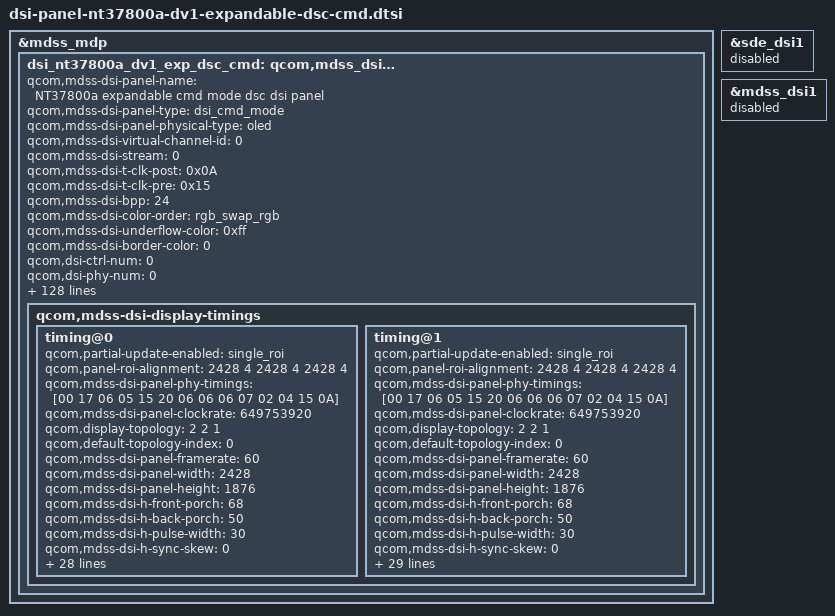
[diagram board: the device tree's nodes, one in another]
/* Copyright (c) 2014, Code Aurora Forum. All rights reserved.
 *
 * This program is free software; you can redistribute it and/or modify
 * it under the terms of the GNU General Public License version 2 and
 * only version 2 as published by the Free Software Foundation.
 *
 * This program is distributed in the hope that it will be useful,
 * but WITHOUT ANY WARRANTY; without even the implied warranty of
 * MERCHANTABILITY or FITNESS FOR A PARTICULAR PURPOSE.  See the
 * GNU General Public License for more details.
 */

/*
 * ===== 2nd working sample information =====
 *   [ DAh : 0x02, DBh : 0x01, DCh : 0x01 ]
 *  A. IRC(VDC) : not supported
 *  B. CM : supported
 *  C. Demura : White Demura
 *  D. PPA : supported
 *  E. AoD Band : not supported
 */
&mdss_mdp {
    dsi_nt37800a_dv1_exp_dsc_cmd: qcom,mdss_dsi_nt37800a_dv1_exp_dsc_cmd {
    qcom,mdss-dsi-panel-name = "NT37800a expandable cmd mode dsc dsi panel";
		qcom,mdss-dsi-panel-type = "dsi_cmd_mode";
		qcom,mdss-dsi-panel-physical-type = "oled";
		qcom,mdss-dsi-virtual-channel-id = <0>;
		qcom,mdss-dsi-stream = <0>;
		qcom,mdss-dsi-t-clk-post = <0x0A>;
		qcom,mdss-dsi-t-clk-pre = <0x15>;
		qcom,mdss-dsi-bpp = <24>;
		qcom,mdss-dsi-color-order = "rgb_swap_rgb";
		qcom,mdss-dsi-underflow-color = <0xff>;
		qcom,mdss-dsi-border-color = <0>;
		qcom,dsi-ctrl-num = <0>;
		qcom,dsi-phy-num = <0>;
		qcom,dsi-select-clocks = "mux_byte_clk0", "mux_pixel_clk0";
		qcom,mdss-dsi-traffic-mode = "burst_mode";
		qcom,mdss-dsi-lane-map = "lane_map_0123";
		qcom,mdss-dsi-bllp-eof-power-mode;
		qcom,mdss-dsi-bllp-power-mode;
		qcom,mdss-dsi-lane-0-state;
		qcom,mdss-dsi-lane-1-state;
		qcom,mdss-dsi-lane-2-state;
		qcom,mdss-dsi-lane-3-state;
		qcom,mdss-dsi-reset-sequence = <1 10>, <0 2>, <1 10>;
		qcom,mdss-dsi-dma-trigger = "trigger_sw";
		qcom,mdss-dsi-mdp-trigger = "none";
		qcom,mdss-dsi-te-pin-select = <1>;
		qcom,mdss-dsi-wr-mem-start = <0x2c>;
		qcom,mdss-dsi-wr-mem-continue = <0x3c>;
		qcom,mdss-dsi-te-dcs-command = <1>;
		//qcom,mdss-dsi-te-check-enable;
		//qcom,mdss-dsi-te-using-te-pin;
		qcom,mdss-dsi-lp11-init;
		qcom,mdss-dsi-tx-eot-append;
		qcom,ulps-enabled;

		/***************************** HDR *******************************/
		qcom,mdss-dsi-panel-hdr-enabled;
		qcom,mdss-dsi-panel-hdr-color-primaries = <14500 15500 32000
			17000 15500 30000 8000 3000>;
		qcom,mdss-dsi-panel-peak-brightness = <4200000>;
		qcom,mdss-dsi-panel-blackness-level = <3230>;

		qcom,mdss-pan-physical-width-dimension = <156>;
		qcom,mdss-pan-physical-height-dimension = <121>;

		/***************** Display Control ***********************/
		lge,mdss-dsi-reset-keep-high-after-off-cmd = <180>;

		lge,mdss-dsi-disp-ctrl-command-1 = [
			15 01 00 00 00 00 02 53 20
		];
		lge,mdss-dsi-disp-ctrl-command-1-state = "dsi_lp_mode";
		lge,mdss-dsi-disp-ctrl-command-2 = [
			15 01 00 00 00 00 02 55 00
			39 00 00 00 00 00 06 F0 55 AA 52 08 00
			15 00 00 00 00 00 02 6F 03
			39 00 00 00 00 00 02 D3 00
			39 01 00 00 00 00 06 F0 55 AA 52 00 00
		];
		lge,mdss-dsi-disp-ctrl-command-2-state = "dsi_lp_mode";

		/***************** Color Manager ***********************/
		lge,use-expandscreen-control;
		lge,use-color-manager;
		lge,color-manager-default-status = <1>;
		lge,mdss-dsi-color-manager-mode-table = <0 1>, <1 1>, <2 1>, <3 1>;

		lge,mdss-dsi-saturation-command = [
		39 00 00 00 00 00 06 F0 55 AA 52 08 00
		39 00 00 00 00 00 2E D1 38 36 37 37 36 36 36 39 33 29 2D 29 26 31 33 35 35 36 36 36 36 34 35 35 01 01 01 01 01 01 01 01 01 01 01 01 01 06 0C 03 09 0F 68 88 00
		39 01 00 00 00 00 06 F0 55 AA 52 00 00
		];
		lge,mdss-dsi-saturation-command-state = "dsi_hs_mode";

		lge,mdss-dsi-hue-command = [
		39 00 00 00 00 00 06 F0 55 AA 52 08 00
		39 00 00 00 00 00 34 D2 77 0C 40 96 83 93 80 7E 63 58 40 40 40 68 7E 78 94 94 94 8C 7A 7A 7A 7A 7D 86 8A 80 80 80 80 80 80 80 80 80 80 80 80 80 80 80 80 80 80 80 80 80 80 80 80
		39 01 00 00 00 00 06 F0 55 AA 52 00 00
		];
		lge,mdss-dsi-hue-command-state = "dsi_hs_mode";

		lge,mdss-dsi-sharpness-command = [
		39 00 00 00 00 00 06 F0 55 AA 52 08 00
		39 00 00 00 00 00 07 D3 02 00 00 01 10 00
		39 01 00 00 00 00 06 F0 55 AA 52 00 00
		];
		lge,mdss-dsi-sharpness-command-state = "dsi_hs_mode";

		lge,mdss-dsi-cm-natural = [
		39 00 00 00 00 00 06 F0 55 AA 52 08 00
		15 00 00 00 00 00 02 6F 00
		39 00 00 00 00 00 13 CE 00 40 40 40 40 3D 3D 3D 3D 40 40 40 40 40 40 40 40 40
		15 00 00 00 00 00 02 6F 13
		39 00 00 00 00 00 12 CE 45 45 45 45 45 45 45 45 45 45 45 45 45 45 45 45 40
		15 00 00 00 00 00 02 6F 24
		39 00 00 00 00 00 12 CE 42 42 42 42 42 42 42 42 42 42 42 42 42 42 42 40 40
		15 00 00 00 00 00 02 6F 35
		39 00 00 00 00 00 12 CE 40 40 40 40 40 40 40 40 40 40 40 40 40 40 40 40 40
		39 00 00 00 00 00 2E D1 38 36 37 37 36 36 36 39 33 29 2D 29 26 31 33 35 35 36 36 36 36 34 35 35 01 01 01 01 01 01 01 01 01 01 01 01 01 06 0C 03 09 0F 68 88 00
		39 00 00 00 00 00 34 D2 77 0C 40 96 83 93 80 7E 63 58 40 40 40 68 7E 78 94 94 94 8C 7A 7A 7A 7A 7D 86 8A 80 80 80 80 80 80 80 80 80 80 80 80 80 80 80 80 80 80 80 80 80 80 80 80
		39 01 00 00 00 00 06 F0 55 AA 52 00 00
		];
		lge,mdss-dsi-cm-natural-state = "dsi_hs_mode";

		lge,mdss-dsi-cm-vivid = [
		39 00 00 00 00 00 06 F0 55 AA 52 08 00
		15 00 00 00 00 00 02 6F 00
		39 00 00 00 00 00 13 CE 00 40 40 40 40 40 40 40 40 40 40 40 40 40 40 40 40 40
		15 00 00 00 00 00 02 6F 13
		39 00 00 00 00 00 12 CE 40 40 40 40 40 40 40 40 40 40 40 40 40 40 40 40 40
		15 00 00 00 00 00 02 6F 24
		39 00 00 00 00 00 12 CE 40 40 40 40 40 40 40 40 40 40 40 40 40 40 40 40 40
		15 00 00 00 00 00 02 6F 35
		39 00 00 00 00 00 12 CE 40 40 40 40 40 40 40 40 40 40 40 40 40 40 40 40 40
		39 00 00 00 00 00 2E D1 50 35 35 35 50 50 50 50 50 50 50 50 50 50 50 50 50 50 50 50 50 50 50 50 01 01 01 01 01 01 01 01 01 01 01 01 00 06 0C 03 09 0F 68 88 00
		39 00 00 00 00 00 34 D2 77 0C 40 80 80 95 80 80 80 80 80 80 80 80 80 80 80 80 80 80 80 80 80 80 80 80 80 80 80 80 80 80 80 80 80 80 80 80 80 80 80 80 80 80 80 80 80 80 80 80 80
		39 01 00 00 00 00 06 F0 55 AA 52 00 00
		];
		lge,mdss-dsi-cm-vivid-state = "dsi_hs_mode";

		lge,mdss-dsi-cm-cinema = [
		39 00 00 00 00 00 06 F0 55 AA 52 08 00
		15 00 00 00 00 00 02 6F 00
		39 00 00 00 00 00 13 CE 00 40 40 44 44 44 44 44 44 44 44 44 44 44 44 44 44 40
		15 00 00 00 00 00 02 6F 13
		39 00 00 00 00 00 12 CE 40 40 40 40 40 40 40 40 40 40 40 40 40 40 40 40 40
		15 00 00 00 00 00 02 6F 24
		39 00 00 00 00 00 12 CE 43 43 43 43 43 43 43 43 43 43 43 48 48 48 48 48 50
		15 00 00 00 00 00 02 6F 35
		39 00 00 00 00 00 12 CE 44 44 44 44 44 44 44 44 44 44 44 44 44 44 44 44 45
		39 00 00 00 00 00 2E D1 35 35 35 35 35 35 37 37 38 35 30 2C 2C 2C 30 32 35 35 35 35 35 34 33 35 44 14 11 11 11 11 11 15 11 11 21 44 00 06 0C 03 09 0F 68 88 00
		39 00 00 00 00 00 34 D2 77 0C 40 80 80 8D 85 80 80 70 60 50 60 7A 80 80 80 8A 8A 8A 80 7B 7B 78 76 74 80 80 80 80 80 80 80 80 80 80 80 80 80 80 80 80 80 80 80 80 80 80 80 80 80
		39 01 00 00 00 00 06 F0 55 AA 52 00 00
		];
		lge,mdss-dsi-cm-cinema-state = "dsi_hs_mode";

		/************************ Brightness ******************************/
		/* Brightness Map List */
		lge,blmap = <
			0
			16 16 16 16 16 16 16 16 16 16 16 16 16 16 16 17 17 18 18 19
			19 21 22 24 26 29 31 34 36 39 42 44 47 50 53 56 60 63 66 69
			72 75 79 82 85 88 91 94 98 102 106 110 114 119 123 127 132 136 141 145
			149 153 158 162 167 171 176 180 185 189 194 198 203 207 211 216 221 225 229 234
			239 243 248 252 257 261 266 270 275 279 284 288 292 297 301 306 310 314 319 324
			329 334 339 344 349 353 358 363 367 372 377 381 386 390 395 400 404 408 413 417
			422 427 432 438 443 448 453 458 463 468 473 478 483 488 493 498 503 508 513 518
			522 527 532 537 542 546 551 555 560 565 570 575 580 584 589 594 599 604 608 613
			618 623 628 632 637 642 647 651 656 661 665 670 674 679 683 688 692 697 701 706
			710 715 719 723 728 732 737 741 745 749 753 757 762 766 770 775 779 783 787 792
			796 800 804 808 812 816 820 824 829 833 837 841 846 850 855 859 863 868 872 876
			880 884 889 893 897 902 906 910 914 918 923 927 931 936 940 944 948 952 956 960
			965 969 973 977 982 986 990 994 998 1002 1006 1011 1015 1019 1024 1024 1024 1024 1024 1024
			1024 1024 1024 1024 1024 1024 1024 1024 1025 1025 1025 1025 1025 1025 1026 1026 1026 1026 1027 1027
			1027 1028 1028 1028 1029 1029 1030 1030 1030 1031 1031 1032 1032 1033 1033 1034 1035 1035 1036 1036
			1037 1038 1038 1039 1040 1041 1042 1043 1043 1044 1045 1046 1047 1048 1050 1051 1052 1053 1054 1055
			1056 1058 1059 1094 1126 1151 1184 1227 1261 1283 1320 1351 1406 1428 1474 1508 1531 1571 1612 1656
			1678 1742 1751 1803 1846 1888 1915 1978 2027 2049 2121 2145 2194 2239 2285 2342 2381 2433 2486 2528
			2558 2623 2651 2729 2756
		>;

		lge,blmap-hl = <
			0
			50 50 50 50 50 50 50 50 50 50 50 50 51 52 52 54 55 57 59 60
			62 65 67 70 73 76 79 82 85 89 92 96 100 105 110 115 121 126 131 137
			142 148 153 159 165 171 177 183 188 194 200 206 212 219 225 231 237 243 249 255
			262 268 274 280 286 292 299 305 311 317 324 331 338 345 351 358 364 371 377 384
			390 397 403 409 415 422 429 437 444 451 459 466 473 480 487 494 501 508 515 522
			528 535 542 548 555 562 569 576 582 589 596 603 610 617 624 630 637 644 651 657
			664 670 677 683 690 696 702 709 715 721 728 734 740 746 752 758 764 770 776 782
			788 794 800 806 812 818 824 830 835 842 848 855 861 867 873 879 885 891 897 903
			909 915 921 927 934 940 946 952 958 964 970 976 982 988 993 999 1005 1012 1018 1024
			1030 1036 1042 1049 1057 1187 1369 1553 1742 1896 2093 2264 2448 2627 2791 2973 3165 3338 3547 3715
			3923 4078 4078 4078 4078 4078 4078 4078 4078 4078 4078 4078 4078 4078 4078 4078 4078 4078 4078 4078
			4078 4078 4078 4078 4078 4078 4078 4078 4078 4078 4078 4078 4078 4078 4078 4078 4078 4078 4078 4078
			4078 4078 4078 4078 4078 4078 4078 4078 4078 4078 4078 4078 4078 4078 4078 4078 4078 4078 4078 4078
			4078 4078 4078 4078 4078 4078 4078 4078 4078 4078 4078 4078 4078 4078 4078 4078 4078 4078 4078 4078
			4078 4078 4078 4078 4078 4078 4078 4078 4078 4078 4078 4078 4078 4078 4078 4078 4078 4078 4078 4078
			4078 4078 4078 4078 4078 4078 4078 4078 4078 4078 4078 4078 4078 4078 4078 4078 4078 4078 4078 4078
			4078 4078 4078 4078 4078 4078 4078 4078 4078 4078 4078 4078 4078 4078 4078 4078 4078 4078 4078 4078
			4078 4078 4078 4078 4078 4078 4078 4078 4078 4078 4078 4078 4078 4078 4078 4078 4078 4078 4078 4078
			4078 4078 4078 4078 4078
		>;

		lge,blmap-ex = <
			0
			519 572 608 634 655 673 785 897 1004 1043 1097 1131 1184 1221 1259 1295 1331 1367 1403 1434
			1469 1504 1530 1562 1596 1620 1650 1674 1701 1726 1756 1775 1803 1829 1846 1878 1966 2042 2131 2204
			2277 2344 2403 2472 2525 2581 2634 2685 2740 2779 2830 2873 2918 2961 3009 3046 3083 3124 3159 3199
			3230 3272 3308 3335 3368 3403 3437 3471 3496 3526 3560 3590 3618 3647 3671 3720 3760 3798 3835 3871
			3907 3945 3978 3982 3984 3987 3989 3992 3995 3997 4000 4003 4005 4007 4009 4012 4014 4014 4015 4016
			4017 4018 4019 4020 4021 4022 4023 4024 4025 4026 4026 4027 4028 4029 4030 4032 4035 4037 4040 4042
			4045 4048 4051 4053 4055 4058 4060 4062 4064 4067 4069 4071 4073 4076 4076 4076 4076 4076 4076 4076
			4077 4078 4079 4081 4082 4083 4084 4085 4086 4087 4089 4090 4091 4092 4093 4094 4094 4094 4094 4094
			4094 4094 4094 4094 4094 4094 4094 4094 4094 4094 4094 4094 4094 4094 4094 4094 4094 4094 4094 4094
			4094 4094 4094 4094 4094 4094 4094 4094 4094 4094 4094 4094 4094 4094 4094 4094 4094 4094 4094 4094
			4094 4094 4094 4094 4094 4094 4094 4094 4094 4094 4094 4094 4094 4094 4094 4094 4094 4094 4094 4094
			4094 4094 4094 4094 4094 4094 4094 4094 4094 4094 4094 4094 4094 4094 4094 4094 4094 4094 4094 4094
			4094 4094 4094 4094 4094 4094 4094 4094 4094 4094 4094 4094 4094 4094 4094
		>;

		lge,blmap-hdr = <
			0
			16 16 16 16 16 16 16 16 16 16 16 16 16 16 17 17 17 18 19 19
			21 23 25 27 29 32 35 38 41 44 47 50 53 57 60 63 67 70 74 77
			81 84 87 91 95 98 103 107 112 116 121 126 130 135 140 145 149 154 159 164
			169 174 179 183 188 193 198 203 208 212 217 222 227 232 237 242 247 252 257 261
			266 271 276 281 286 291 295 300 305 310 315 320 325 330 336 341 346 352 357 362
			367 372 377 382 387 392 397 402 406 411 416 421 427 432 438 444 449 455 461 466
			471 477 482 488 493 499 504 509 514 520 525 530 535 541 545 550 556 561 566 571
			576 582 587 592 597 603 608 613 619 624 629 634 639 644 649 655 660 665 670 674
			679 684 689 694 699 704 708 713 718 723 728 733 737 742 746 751 755 760 765 769
			774 779 783 788 792 797 802 806 810 815 819 824 828 833 837 842 847 852 857 861
			866 870 875 879 884 889 893 898 903 907 912 916 921 926 930 935 940 944 949 953
			958 962 967 971 976 981 985 989 994 998 1003 1008 1012 1017 1022 1026 1031 1035 1040 1045
			1051 1056 1136 1275 1416 1539 1674 1809 1949 2094 2230 2357 2496 2631 2756 2756 2756 2756 2756 2756
			2757 2757 2757 2758 2758 2759 2761 2761 2782 2783 2784 2785 2786 2787 2788 2790 2791 2792 2794 2795
			2797 2813 2825 2829 2833 2838 2841 2845 2848 2852 2855 2859 2883 2887 2891 2895 2909 2927 2933 2938
			2944 2950 2956 2968 2982 2989 2995 3015 3025 3031 3038 3046 3056 3070 3086 3104 3123 3133 3148 3165
			3176 3186 3196 3226 3233 3246 3267 3279 3307 3317 3327 3337 3365 3374 3409 3420 3430 3447 3470 3504
			3513 3542 3556 3566 3574 3606 3633 3650 3683 3694 3707 3742 3756 3784 3797 3810 3844 3873 3894 3928
			3942 3981 3993 4029 4065
		>;

//		lge,use-irc-ctrl; // ENG2 : NOT SUPPORTED
		lge,mdss-dsi-irc-command = [
			39 00 00 00 00 00 06 F0 55 AA 52 08 08
			15 00 00 00 00 00 02 B9 00
			39 01 00 00 00 00 06 F0 55 AA 52 00 00
		];
		lge,mdss-dsi-irc-command-state = "dsi_hs_mode";

		lge,use-hl-mode;
//		lge,use-bc-dim;
//		lge,bc-dimming-work;
		lge,mdss-dsi-bc-default-command = [
			39 00 00 00 00 00 06 F0 55 AA 52 08 00
			15 00 00 00 00 00 02 6F 02
			39 00 00 00 00 00 03 B2 01 01
			39 01 00 00 00 00 06 F0 55 AA 52 00 00
		];
		lge,mdss-dsi-bc-default-command-state = "dsi_hs_mode";

		lge,use-vr-lp-mode;
		lge,mdss-dsi-vr-lp-mode-on-command = [
			39 00 00 00 00 00 06 F0 55 AA 52 08 00
			15 00 00 00 00 00 02 6F 0F
			15 00 00 00 00 00 02 B2 00
			39 00 00 00 00 00 27 B4 06 86 06 86 05 0C 05 0C 03 1E 03 1E 01 68 01 68 05 32 05 32 05 32 05 32 05 32 05 32 05 32 05 32 05 32 05 32 05 32
			39 01 00 00 00 00 06 F0 55 AA 52 00 00
		];
		lge,mdss-dsi-vr-lp-mode-off-command = [
			39 00 00 00 00 00 06 F0 55 AA 52 08 00
			15 00 00 00 00 00 02 6F 0F
			15 00 00 00 00 00 02 B2 80
			39 00 00 00 00 00 27 B4 06 AE 06 AE 06 AE 06 2C 06 2C 04 B0 04 B0 02 8A 02 8A 00 6E 00 6E 00 6E 00 6E 04 B0 04 B0 02 8A 00 6E 00 6E 00 6E
			39 01 00 00 00 00 06 F0 55 AA 52 00 00
		];
		lge,mdss-dsi-vr-lp-command-state = "dsi_lp_mode";
		lge,blmap-vr = < 0 528 >;

		lge,mdss-dsi-expandable-area-command = [
			39 00 00 00 00 00 05 30 03 20 07 53
			39 01 00 00 00 00 05 32 00 00 02 AF
		];
		lge,mdss-dsi-expandable-area-command-state = "dsi_hs_mode";

		lge,mdss-dsi-expandable-area-enable-command = [
			15 01 00 00 00 00 02 63 00
			05 01 00 00 00 00 01 13
			15 01 00 00 00 00 02 84 03
		];
		lge,mdss-dsi-expandable-area-enable-command-state = "dsi_hs_mode";

		/*************************** AOD **********************************/
		lge,use-ambient;
		lge,aod-interface-data = "partial", "partial", "partial";
		lge,disp-br-ctrl-ext-supported;
		lge,ddic-dsi-br-ctrl-ext-command = [
			39 01 00 00 00 00 05 51 00 00 00 00
		];

		lge,mdss-dsi-nolp-command = [
			05 01 00 00 00 00 01 38
			15 01 00 00 00 00 02 65 00
			39 01 00 00 00 00 01 2C
			39 01 00 00 00 00 06 F0 55 AA 52 08 04
			15 01 00 00 00 00 02 D0 B2
			39 01 00 00 00 00 06 F0 55 AA 52 00 00
		];
		lge,mdss-dsi-nolp-command-state = "dsi_lp_mode";
		lge,mdss-dsi-lp2-command = [
			15 01 00 00 00 00 02 84 00
			39 01 00 00 00 00 06 F0 55 AA 52 08 04
			15 01 00 00 00 00 02 D0 22
			39 01 00 00 00 00 06 F0 55 AA 52 00 00
			05 01 00 00 00 00 01 39
			15 01 00 00 00 00 02 65 01
			39 01 00 00 00 00 01 2C
			15 01 00 00 00 00 02 84 03
		];
		lge,mdss-dsi-lp2-command-state = "dsi_lp_mode";

		/************************* Factory *********************************/
		lge,use-line-detect;
		lge,detect-vert-line-restore-command = [
			39 00 00 00 00 00 06 F0 55 AA 52 08 01
			39 00 00 00 00 00 03 B0 00 00
			39 00 00 00 00 00 03 B3 03 03
			39 00 00 00 00 00 11 B7 14 14 14 14 14 14 14 14 14 14 14 14 14 14 14 14
			39 00 00 00 00 00 03 B1 00 00
			39 00 00 00 00 00 03 B4 03 03
			39 00 00 00 00 00 11 B8 41 41 41 41 41 41 41 41 41 41 41 41 41 41 41 41
			39 01 00 00 00 00 06 F0 55 AA 52 00 00
		];
		lge,detect-vert-line-restore-command-state = "dsi_hs_mode";
		lge,detect-black-vert-line-command = [
			39 00 00 00 00 00 06 F0 55 AA 52 08 01
			39 00 00 00 00 00 03 B0 00 00
			39 00 00 00 00 00 03 B3 03 03
			39 00 00 00 00 00 11 B7 32 32 32 32 32 32 32 32 32 32 32 32 32 32 32 32
			39 00 00 00 00 00 03 B1 00 00
			39 00 00 00 00 00 03 B4 03 03
			39 00 00 00 00 00 11 B8 2D 2D 2D 2D 2D 2D 2D 2D 2D 2D 2D 2D 2D 2D 2D 2D
			39 01 00 00 00 00 06 F0 55 AA 52 00 00
		];
		lge,detect-black-vert-line-command-state = "dsi_hs_mode";
		lge,detect-white-vert-line-command = [
			39 00 00 00 00 00 06 F0 55 AA 52 08 01
			39 00 00 00 00 00 03 B0 00 00
			39 00 00 00 00 00 03 B3 03 03
			39 00 00 00 00 00 11 B7 0A 0A 0A 0A 0A 0A 0A 0A 0A 0A 0A 0A 0A 0A 0A 0A
			39 00 00 00 00 00 03 B1 00 00
			39 00 00 00 00 00 03 B4 03 03
			39 00 00 00 00 00 11 B8 5F 5F 5F 5F 5F 5F 5F 5F 5F 5F 5F 5F 5F 5F 5F 5F
			39 01 00 00 00 00 06 F0 55 AA 52 00 00
		];
		lge,detect-white-vert-line-command-state = "dsi_hs_mode";

		lge,use-tc-perf;
		lge,mdss-dsi-tc-perf-on-command = [
			39 00 00 00 00 00 06 F0 55 AA 52 08 00
			15 00 00 00 00 00 02 6F 0F
			15 00 00 00 00 00 02 B2 00
			39 00 00 00 00 00 27 B4 06 86 06 86 05 0C 05 0C 03 1E 03 1E 01 68 01 68 00 26 00 26 00 26 00 26 00 26 00 26 00 26 00 26 00 26 00 26 00 08
			39 01 00 00 00 00 06 F0 55 AA 52 00 00
		];
		lge,mdss-dsi-tc-perf-on-command-state = "dsi_hs_mode";

		lge,mdss-dsi-tc-perf-off-command = [
			39 00 00 00 00 00 06 F0 55 AA 52 08 00
			15 00 00 00 00 00 02 6F 0F
			15 00 00 00 00 00 02 B2 80
			39 00 00 00 00 00 27 B4 06 AE 06 AE 06 AE 06 2C 06 2C 04 B0 04 B0 02 8A 02 8A 00 6E 00 6E 00 6E 00 6E 04 B0 04 B0 02 8A 00 6E 00 6E 00 6E
			39 01 00 00 00 00 06 F0 55 AA 52 00 00
		];
		lge,mdss-dsi-tc-perf-off-command-state = "dsi_hs_mode";

		lge,send-partial-update-cmds-to-hs;

		qcom,mdss-dsi-display-timings {
			timing@0{
				qcom,partial-update-enabled = "single_roi";
				qcom,panel-roi-alignment = <2428 4 2428 4 2428 4>;
				qcom,mdss-dsi-panel-phy-timings = [00 17 06 05 15 20 06 06 06 07 02 04 15 0A]; /* To Do */
				qcom,mdss-dsi-panel-clockrate = <649753920>;
				qcom,display-topology = <2 2 1>;
				qcom,default-topology-index = <0>;
				qcom,mdss-dsi-panel-framerate = <60>;
				qcom,mdss-dsi-panel-width = <2428>;
				qcom,mdss-dsi-panel-height = <1876>;
				qcom,mdss-dsi-h-front-porch = <68>;
				qcom,mdss-dsi-h-back-porch = <50>;
				qcom,mdss-dsi-h-pulse-width = <30>;
				qcom,mdss-dsi-h-sync-skew = <0>;
				qcom,mdss-dsi-v-back-porch = <2>;
				qcom,mdss-dsi-v-front-porch = <4>;
				qcom,mdss-dsi-v-pulse-width = <2>;
				qcom,mdss-dsi-h-left-border = <0>;
				qcom,mdss-dsi-h-right-border = <0>;
				qcom,mdss-dsi-v-top-border = <0>;
				qcom,mdss-dsi-v-bottom-border = <0>;
				qcom,mdss-dsi-h-sync-pulse = <0>;
				//qcom,mdss-mdp-transfer-time-us = <15000>;

				qcom,mdss-dsi-on-command = [
					39 01 00 00 00 00 06 F0 55 AA 52 08 00
					15 01 00 00 00 00 02 B2 09
					39 01 00 00 00 00 19 CC 40 40 40 40 40 40 40 40 40 40 40 40 40 40 40 40 40 50 60 70 58 68 78 77
					15 01 00 00 00 00 02 6F 46
					39 01 00 00 00 00 12 CE 40 40 40 40 40 40 40 40 40 40 40 40 40 40 40 40 40
					15 01 00 00 00 00 02 6F 57
					39 01 00 00 00 00 12 CE 40 40 40 40 40 40 40 40 40 40 40 40 40 40 40 40 40
					15 01 00 00 00 00 02 6F 00
					39 01 00 00 00 00 03 D0 77 00
					15 01 00 00 00 00 02 6F 01
					39 01 00 00 00 00 03 D4 00 00
					39 01 00 00 00 00 19 DE 00 00 00 00 00 00 00 00 00 00 00 00 10 00 00 00 00 00 00 00 10 00 00 00
					39 01 00 00 00 00 06 F0 55 AA 52 08 01
					15 01 00 00 00 00 02 6F 02
					15 01 00 00 00 00 02 D2 00
					39 01 00 00 00 00 07 B7 14 14 14 14 14 14
					39 01 00 00 00 00 07 B8 41 41 41 41 41 41
					39 01 00 00 00 00 06 F0 55 AA 52 08 05
					15 01 00 00 00 00 02 6F 02
					15 01 00 00 00 00 02 B0 01
					39 01 00 00 00 00 06 F0 55 AA 52 08 07
					39 01 00 00 00 00 06 B0 84 40 78 70 00
					39 01 00 00 00 00 06 B1 0C 1C 00 1C 0C
					39 01 00 00 00 00 0A B2 30 30 30 30 30 30 30 30 30
					15 01 00 00 00 00 02 6F 36
					39 01 00 00 00 00 13 B2 32 32 32 32 32 32 32 32 32 77 77 77 77 77 77 77 77 77
					15 01 00 00 00 00 02 6F 09
					39 01 00 00 00 00 0A B2 90 90 90 90 90 90 90 90 90
					15 01 00 00 00 00 02 6F 48
					39 01 00 00 00 00 13 B2 33 33 33 33 33 33 33 33 33 79 79 79 79 79 79 79 79 79
					15 01 00 00 00 00 02 6F 12
					39 01 00 00 00 00 0A B2 FC FC FC FC FC FC FC FC FC
					15 01 00 00 00 00 02 6F 5A
					39 01 00 00 00 00 13 B2 03 03 03 03 03 03 03 03 03 9B 9B 9B 9B 9B 9B 9B 9B 9B
					15 01 00 00 00 00 02 6F 1B
					39 01 00 00 00 00 0A B2 90 90 90 90 90 90 90 90 90
					15 01 00 00 00 00 02 6F 6C
					39 01 00 00 00 00 13 B2 33 33 33 33 33 33 33 33 33 79 79 79 79 79 79 79 79 79
					15 01 00 00 00 00 02 6F 24
					39 01 00 00 00 00 0A B2 30 30 30 30 30 30 30 30 30
					15 01 00 00 00 00 02 6F 7E
					39 01 00 00 00 00 13 B2 32 32 32 32 32 32 32 32 32 77 77 77 77 77 77 77 77 77
					15 01 00 00 00 00 02 6F 2D
					39 01 00 00 00 00 0A B2 CC CC CC CC CC CC CC CC CC
					15 01 00 00 00 00 02 6F 90
					39 01 00 00 00 00 13 B2 03 03 03 03 03 03 03 03 03 3A 3A 3A 3A 3A 3A 3A 3A 3A
					15 01 00 00 00 00 02 B4 C0
					15 01 00 00 00 00 02 6F 01
					39 01 00 00 00 00 0D B4 80 80 80 80 60 80 60 80 80 80 80 80
					39 01 00 00 00 00 03 B7 00 00
					39 01 00 00 00 00 06 F0 55 AA 52 00 00
					39 01 00 00 00 00 05 FF AA 55 A5 80
					15 01 00 00 00 00 02 6F 50
					15 01 00 00 00 00 02 FB 00
					15 01 00 00 00 00 02 6F 61
					15 01 00 00 00 00 02 FB 80
					39 01 00 00 00 00 05 FF AA 55 A5 81
					39 01 00 00 00 00 05 FF AA 55 A5 00
					15 01 00 00 00 00 02 35 00
					39 01 00 00 00 00 05 3B 00 10 00 10
					39 01 00 00 00 00 05 51 00 00 0F FF
					15 01 00 00 00 00 02 53 20
					15 01 00 00 00 00 02 55 00
					15 01 00 00 00 00 02 03 01
					39 01 00 00 00 00 05 2A 00 00 09 7B
					39 01 00 00 00 00 05 2B 00 00 07 53
					39 01 00 00 00 00 05 30 02 AE 07 53
					39 01 00 00 00 00 05 31 00 00 09 7B
					39 01 00 00 00 00 05 32 00 00 02 AD
					39 01 00 00 00 00 05 33 00 00 09 7B
					15 01 00 00 00 00 02 63 03
					15 01 00 00 00 00 02 84 03
					15 01 00 00 00 00 02 90 81
					39 01 00 00 00 00 13 91 89 28 00 04 C2 00 03 60 00 72 00 10 20 00 0B 25 10 D0
					15 01 00 00 00 00 02 2C 00
					05 01 00 00 78 00 01 11
					05 01 00 00 00 00 01 29
					];

				qcom,mdss-dsi-post-panel-on-command = [
					//05 01 00 00 78 00 01 12
					//39 01 00 00 00 00 03 51 07 FF
				];

				qcom,mdss-dsi-off-command = [
					05 01 00 00 00 00 01 28
					05 01 00 00 20 00 01 10
				];

				qcom,compression-mode = "dsc";
				qcom,mdss-dsc-version = <0x11>;
				qcom,mdss-dsc-scr-version = <0x0>;
				qcom,mdss-dsc-slice-height = <4>;
				qcom,mdss-dsc-slice-width = <1214>;
				qcom,mdss-dsc-slice-per-pkt = <2>;
				qcom,mdss-dsc-bit-per-component = <8>;
				qcom,mdss-dsc-bit-per-pixel = <8>;
				qcom,lm-split = <1214 1214>;
				qcom,mdss-dsc-encoders = <2>;
				qcom,mdss-dsc-block-prediction-enable;

				qcom,mdss-dsi-on-command-state = "dsi_lp_mode";
				qcom,mdss-dsi-off-command-state = "dsi_lp_mode";

				qcom,mode-control-dsi-state = "dsi_lp_mode";
				qcom,mdss-dsi-pps-command-state = "dsi_hs_mode";
			};

			timing@1{
				qcom,partial-update-enabled = "single_roi";
				qcom,panel-roi-alignment = <2428 4 2428 4 2428 4>;
				qcom,mdss-dsi-panel-phy-timings = [00 17 06 05 15 20 06 06 06 07 02 04 15 0A]; /* To Do */
				qcom,mdss-dsi-panel-clockrate = <649753920>;
				qcom,display-topology = <2 2 1>;
				qcom,default-topology-index = <0>;
				qcom,mdss-dsi-panel-framerate = <60>;
				qcom,mdss-dsi-panel-width = <2428>;
				qcom,mdss-dsi-panel-height = <1876>;
				qcom,mdss-dsi-h-front-porch = <68>;
				qcom,mdss-dsi-h-back-porch = <50>;
				qcom,mdss-dsi-h-pulse-width = <30>;
				qcom,mdss-dsi-h-sync-skew = <0>;
				qcom,mdss-dsi-v-back-porch = <2>;
				qcom,mdss-dsi-v-front-porch = <4>;
				qcom,mdss-dsi-v-pulse-width = <2>;
				qcom,mdss-dsi-h-left-border = <0>;
				qcom,mdss-dsi-h-right-border = <0>;
				qcom,mdss-dsi-v-top-border = <0>;
				qcom,mdss-dsi-v-bottom-border = <0>;
				qcom,mdss-dsi-h-sync-pulse = <0>;
				//qcom,mdss-mdp-transfer-time-us = <15000>;
				lge,mdss-dsi-panel-framerate-div = <2>;

				qcom,mdss-dsi-on-command = [
					39 01 00 00 00 00 06 F0 55 AA 52 08 00
					15 01 00 00 00 00 02 B2 09
					39 01 00 00 00 00 19 CC 40 40 40 40 40 40 40 40 40 40 40 40 40 40 40 40 40 50 60 70 58 68 78 77
					15 01 00 00 00 00 02 6F 46
					39 01 00 00 00 00 12 CE 40 40 40 40 40 40 40 40 40 40 40 40 40 40 40 40 40
					15 01 00 00 00 00 02 6F 57
					39 01 00 00 00 00 12 CE 40 40 40 40 40 40 40 40 40 40 40 40 40 40 40 40 40
					15 01 00 00 00 00 02 6F 00
					39 01 00 00 00 00 03 D0 77 00
					15 01 00 00 00 00 02 6F 01
					39 01 00 00 00 00 03 D4 00 00
					39 01 00 00 00 00 19 DE 00 00 00 00 00 00 00 00 00 00 00 00 10 00 00 00 00 00 00 00 10 00 00 00
					39 01 00 00 00 00 06 F0 55 AA 52 08 01
					15 01 00 00 00 00 02 6F 02
					15 01 00 00 00 00 02 D2 00
					39 01 00 00 00 00 07 B7 14 14 14 14 14 14
					39 01 00 00 00 00 07 B8 41 41 41 41 41 41
					39 01 00 00 00 00 06 F0 55 AA 52 08 05
					15 01 00 00 00 00 02 6F 02
					15 01 00 00 00 00 02 B0 01
					39 01 00 00 00 00 06 F0 55 AA 52 08 07
					39 01 00 00 00 00 06 B0 84 40 78 70 00
					39 01 00 00 00 00 06 B1 0C 1C 00 1C 0C
					39 01 00 00 00 00 0A B2 30 30 30 30 30 30 30 30 30
					15 01 00 00 00 00 02 6F 36
					39 01 00 00 00 00 13 B2 32 32 32 32 32 32 32 32 32 77 77 77 77 77 77 77 77 77
					15 01 00 00 00 00 02 6F 09
					39 01 00 00 00 00 0A B2 90 90 90 90 90 90 90 90 90
					15 01 00 00 00 00 02 6F 48
					39 01 00 00 00 00 13 B2 33 33 33 33 33 33 33 33 33 79 79 79 79 79 79 79 79 79
					15 01 00 00 00 00 02 6F 12
					39 01 00 00 00 00 0A B2 FC FC FC FC FC FC FC FC FC
					15 01 00 00 00 00 02 6F 5A
					39 01 00 00 00 00 13 B2 03 03 03 03 03 03 03 03 03 9B 9B 9B 9B 9B 9B 9B 9B 9B
					15 01 00 00 00 00 02 6F 1B
					39 01 00 00 00 00 0A B2 90 90 90 90 90 90 90 90 90
					15 01 00 00 00 00 02 6F 6C
					39 01 00 00 00 00 13 B2 33 33 33 33 33 33 33 33 33 79 79 79 79 79 79 79 79 79
					15 01 00 00 00 00 02 6F 24
					39 01 00 00 00 00 0A B2 30 30 30 30 30 30 30 30 30
					15 01 00 00 00 00 02 6F 7E
					39 01 00 00 00 00 13 B2 32 32 32 32 32 32 32 32 32 77 77 77 77 77 77 77 77 77
					15 01 00 00 00 00 02 6F 2D
					39 01 00 00 00 00 0A B2 CC CC CC CC CC CC CC CC CC
					15 01 00 00 00 00 02 6F 90
					39 01 00 00 00 00 13 B2 03 03 03 03 03 03 03 03 03 3A 3A 3A 3A 3A 3A 3A 3A 3A
					15 01 00 00 00 00 02 B4 C0
					15 01 00 00 00 00 02 6F 01
					39 01 00 00 00 00 0D B4 80 80 80 80 60 80 60 80 80 80 80 80
					39 01 00 00 00 00 03 B7 00 00
					39 01 00 00 00 00 06 F0 55 AA 52 00 00
					39 01 00 00 00 00 05 FF AA 55 A5 80
					15 01 00 00 00 00 02 6F 50
					15 01 00 00 00 00 02 FB 00
					15 01 00 00 00 00 02 6F 61
					15 01 00 00 00 00 02 FB 80
					39 01 00 00 00 00 05 FF AA 55 A5 81
					39 01 00 00 00 00 05 FF AA 55 A5 00
					15 01 00 00 00 00 02 35 00
					39 01 00 00 00 00 05 3B 00 10 00 10
					39 01 00 00 00 00 05 51 00 00 0F FF
					15 01 00 00 00 00 02 53 20
					15 01 00 00 00 00 02 55 00
					15 01 00 00 00 00 02 03 01
					39 01 00 00 00 00 05 2A 00 00 09 7B
					39 01 00 00 00 00 05 2B 00 00 07 53
					39 01 00 00 00 00 05 30 02 AE 07 53
					39 01 00 00 00 00 05 31 00 00 09 7B
					39 01 00 00 00 00 05 32 00 00 02 AD
					39 01 00 00 00 00 05 33 00 00 09 7B
					15 01 00 00 00 00 02 63 03
					15 01 00 00 00 00 02 84 03
					15 01 00 00 00 00 02 90 81
					39 01 00 00 00 00 13 91 89 28 00 04 C2 00 03 60 00 72 00 10 20 00 0B 25 10 D0
					15 01 00 00 00 00 02 2C 00
					05 01 00 00 78 00 01 11
					05 01 00 00 00 00 01 29
					];

				qcom,mdss-dsi-post-panel-on-command = [
					//05 01 00 00 78 00 01 12
					//39 01 00 00 00 00 03 51 07 FF
				];

				qcom,mdss-dsi-off-command = [
					05 01 00 00 00 00 01 28
					05 01 00 00 20 00 01 10
				];

				qcom,compression-mode = "dsc";
				qcom,mdss-dsc-version = <0x11>;
				qcom,mdss-dsc-scr-version = <0x0>;
				qcom,mdss-dsc-slice-height = <4>;
				qcom,mdss-dsc-slice-width = <1214>;
				qcom,mdss-dsc-slice-per-pkt = <2>;
				qcom,mdss-dsc-bit-per-component = <8>;
				qcom,mdss-dsc-bit-per-pixel = <8>;
				qcom,lm-split = <1214 1214>;
				qcom,mdss-dsc-encoders = <2>;
				qcom,mdss-dsc-block-prediction-enable;

				qcom,mdss-dsi-on-command-state = "dsi_lp_mode";
				qcom,mdss-dsi-off-command-state = "dsi_lp_mode";

				qcom,mode-control-dsi-state = "dsi_lp_mode";
				qcom,mdss-dsi-pps-command-state = "dsi_hs_mode";
			};

		};
	};
};

&sde_dsi1 {
	status = "disabled";
};

&mdss_dsi1 {
	status = "disabled";
};
